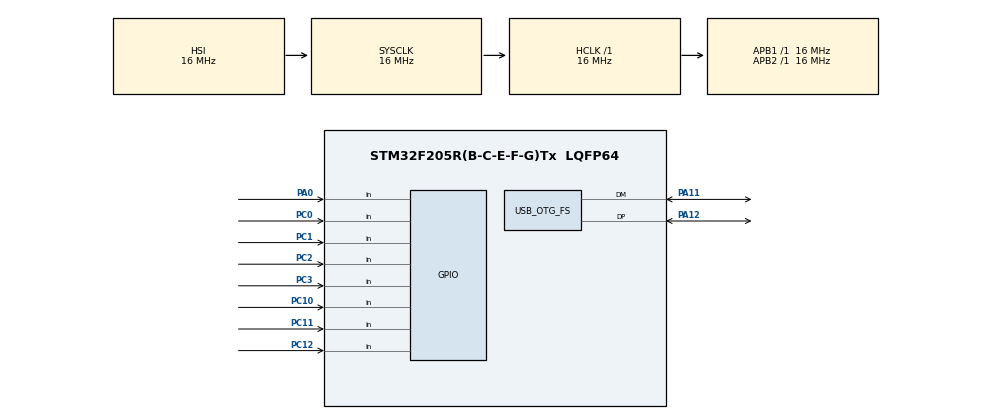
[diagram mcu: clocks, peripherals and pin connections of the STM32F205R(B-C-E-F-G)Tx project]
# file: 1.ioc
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Mcu.Family=STM32F2
Mcu.Name=STM32F205R(B-C-E-F-G)Tx
Mcu.Package=LQFP64
NVIC.FLASH_IRQn=true\:0\:0\:false\:false\:true\:true\:true
NVIC.OTG_FS_IRQn=true\:0\:0\:false\:false\:true\:true\:true
NVIC.PVD_IRQn=true\:0\:0\:false\:false\:true\:true\:true
NVIC.PriorityGroup=NVIC_PRIORITYGROUP_4
NVIC.RCC_IRQn=true\:0\:0\:false\:false\:true\:true\:false
PA0-WKUP.GPIO_PuPd=GPIO_PULLUP
PA0-WKUP.Signal=GPIO_Input
PA11.Mode=Device_Only
PA11.Signal=USB_OTG_FS_DM
PA12.Mode=Device_Only
PA12.Signal=USB_OTG_FS_DP
PC0.GPIO_PuPd=GPIO_PULLUP
PC0.Signal=GPIO_Input
PC1.GPIO_PuPd=GPIO_PULLUP
PC1.Signal=GPIO_Input
PC10.GPIO_PuPd=GPIO_PULLUP
PC10.Signal=GPIO_Input
PC11.GPIO_PuPd=GPIO_PULLUP
PC11.Signal=GPIO_Input
PC12.GPIO_PuPd=GPIO_PULLUP
PC12.Signal=GPIO_Input
PC2.GPIO_PuPd=GPIO_PULLUP
PC2.Signal=GPIO_Input
PC3.GPIO_PuPd=GPIO_PULLUP
PC3.Signal=GPIO_Input
PH0-OSC_IN.Mode=HSE-External-Oscillator
PH0-OSC_IN.Signal=RCC_OSC_IN
PH1-OSC_OUT.Mode=HSE-External-Oscillator
PH1-OSC_OUT.Signal=RCC_OSC_OUT
ProjectManager.HeapSize=0x200
ProjectManager.StackSize=0x400
ProjectManager.TargetToolchain=MDK-ARM V5
RCC.48MHZClocksFreq_Value=48000000
RCC.AHBFreq_Value=16000000
RCC.APB1Freq_Value=16000000
RCC.APB2Freq_Value=16000000
RCC.CortexFreq_Value=16000000
RCC.HSE_VALUE=25000000
RCC.HSI_VALUE=16000000
RCC.LSE_VALUE=32768
RCC.SYSCLKFreq_VALUE=16000000
RCC.VCOOutputFreq_Value=192000000
USB_DEVICE.CLASS_NAME_FS=HID
USB_DEVICE.VirtualMode-HID_FS=Hid
USB_DEVICE.VirtualModeFS=Hid_FS
USB_OTG_FS.VirtualMode=Device_Only
VP_USB_DEVICE_VS_USB_DEVICE_HID_FS.Mode=HID_FS
board=custom

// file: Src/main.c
/* USER CODE BEGIN Header */
/**
  ******************************************************************************
  * @file           : main.c
  * @brief          : Main program body
  ******************************************************************************
  * @attention
  *
  * <h2><center>&copy; Copyright (c) 2019 STMicroelectronics.
  * All rights reserved.</center></h2>
  *
  * This software component is licensed by ST under Ultimate Liberty license
  * SLA0044, the "License"; You may not use this file except in compliance with
  * the License. You may obtain a copy of the License at:
  *                             www.st.com/SLA0044
  *
  ******************************************************************************
  */
/* USER CODE END Header */

#include "main.h"
#include "usb_device.h"
#include "appkeyboard.h"
//#include "appmouse.h"

void SystemClock_Config(void);
static void MX_GPIO_Init(void);

/* USER CODE BEGIN 0 */
int count = 1;
/* USER CODE END 0 */

int main(void)
{
  /* USER CODE BEGIN 1 */
	uint8_t i,j;
  /* USER CODE END 1 */

  /* MCU Configuration--------------------------------------------------------*/

  /* Reset of all peripherals, Initializes the Flash interface and the Systick. */
  HAL_Init();

  /* Configure the system clock */
  SystemClock_Config();

  /* Initialize all configured peripherals */
  MX_GPIO_Init();
	MX_USB_DEVICE_Init();

  /* Infinite loop */
  while (1)
  {
		if(!HAL_GPIO_ReadPin (GPIOA,GPIO_PIN_0))
		{
		count ^= 1;
		USBD_DeInit(&hUsbDeviceFS);
		MX_USB_DEVICE_Init();
		}
		if(count==0)
			{
				i = Key_ReadIOPin();
				if(!i)
					{
						mouseControl();
					}
			}
		else
			{
				j = keyScan();
				if(!j)
					keyboardControl();
				HAL_Delay (100);
			}
  }
}

void SystemClock_Config(void)
{
  RCC_OscInitTypeDef RCC_OscInitStruct = {0};
  RCC_ClkInitTypeDef RCC_ClkInitStruct = {0};

  /** Initializes the CPU, AHB and APB busses clocks
  */
  RCC_OscInitStruct.OscillatorType = RCC_OSCILLATORTYPE_HSI;
  RCC_OscInitStruct.HSIState = RCC_HSI_ON;
  RCC_OscInitStruct.HSICalibrationValue = RCC_HSICALIBRATION_DEFAULT;
  RCC_OscInitStruct.PLL.PLLState = RCC_PLL_ON;
  RCC_OscInitStruct.PLL.PLLSource = RCC_PLLSOURCE_HSI;
  RCC_OscInitStruct.PLL.PLLM = 16;
  RCC_OscInitStruct.PLL.PLLN = 192;
  RCC_OscInitStruct.PLL.PLLP = RCC_PLLP_DIV2;
  RCC_OscInitStruct.PLL.PLLQ = 4;
  if (HAL_RCC_OscConfig(&RCC_OscInitStruct) != HAL_OK)
  {
    Error_Handler();
  }
  /** Initializes the CPU, AHB and APB busses clocks
  */
  RCC_ClkInitStruct.ClockType = RCC_CLOCKTYPE_HCLK|RCC_CLOCKTYPE_SYSCLK
                              |RCC_CLOCKTYPE_PCLK1|RCC_CLOCKTYPE_PCLK2;
  RCC_ClkInitStruct.SYSCLKSource = RCC_SYSCLKSOURCE_HSI;
  RCC_ClkInitStruct.AHBCLKDivider = RCC_SYSCLK_DIV1;
  RCC_ClkInitStruct.APB1CLKDivider = RCC_HCLK_DIV1;
  RCC_ClkInitStruct.APB2CLKDivider = RCC_HCLK_DIV1;

  if (HAL_RCC_ClockConfig(&RCC_ClkInitStruct, FLASH_LATENCY_0) != HAL_OK)
  {
    Error_Handler();
  }
}

static void MX_GPIO_Init(void)
{
  GPIO_InitTypeDef GPIO_InitStruct = {0};

  /* GPIO Ports Clock Enable */
  __HAL_RCC_GPIOH_CLK_ENABLE();
  __HAL_RCC_GPIOC_CLK_ENABLE();
  __HAL_RCC_GPIOA_CLK_ENABLE();

  /*Configure GPIO pins : PC0 PC1 PC2 PC3
                           PC10 PC11 PC12 */
  GPIO_InitStruct.Pin = GPIO_PIN_0|GPIO_PIN_1|GPIO_PIN_2|GPIO_PIN_3
                          |GPIO_PIN_10|GPIO_PIN_11|GPIO_PIN_12;
  GPIO_InitStruct.Mode = GPIO_MODE_INPUT;
  GPIO_InitStruct.Pull = GPIO_PULLUP;
  HAL_GPIO_Init(GPIOC, &GPIO_InitStruct);

  /*Configure GPIO pin : PA0 */
  GPIO_InitStruct.Pin = GPIO_PIN_0;
  GPIO_InitStruct.Mode = GPIO_MODE_INPUT;
  GPIO_InitStruct.Pull = GPIO_PULLUP;
  HAL_GPIO_Init(GPIOA, &GPIO_InitStruct);

}

void Error_Handler(void)
{
}

/************************ (C) COPYRIGHT STMicroelectronics *****END OF FILE****/
